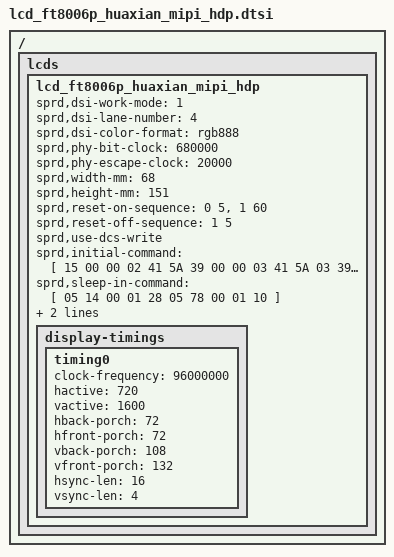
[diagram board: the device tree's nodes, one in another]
/ { lcds {
	lcd_ft8006p_huaxian_mipi_hdp: lcd_ft8006p_huaxian_mipi_hdp {

		sprd,dsi-work-mode = <1>; /* video burst mode*/
		sprd,dsi-lane-number = <4>;
		sprd,dsi-color-format = "rgb888";

		sprd,phy-bit-clock = <680000>;	/* kbps */
		sprd,phy-escape-clock = <20000>;/* kHz */

		sprd,width-mm = <68>;
		sprd,height-mm = <151>;

		sprd,reset-on-sequence = <0 5>, <1 60>;
		sprd,reset-off-sequence = <1 5>;

		sprd,use-dcs-write;

		sprd,initial-command = [
			/*-------------  Display Initial Code Setting  -------------------------*/
			/* Stop reload */
			15 00 00 02 41 5A

			/* VCOM */
			39 00 00 03 41 5A 03
			39 00 00 03 80 A9 00

			/*----------------------LCD initial code start----------------------*/
			/* Blank 9 */
			39 00 00 03 41 5A 09
			39 00 00 06 80 64 00 64 00 00
			/* Blank 10 */
			39 00 00 03 41 5A 0A
			39 00 00 11 80 A5 15 A5 AA A5 88 42 68 A6 03 07 01 5F 46 50 3C
			39 00 00 11 90 0C 0F 22 00 2A 18 64 00 88 03 00 EE EE 00 3F 2A
			39 00 00 11 A0 00 30 02 32 11 0D 60 01 FF FF 03 40 42 0F 94 11
			39 00 00 11 B0 E8 03 00 00 11 0D 60 00 FF FF 03 FF 34 0C 0F 0E
			39 00 00 0b C0 1F 03 00 08 20 34 00 00 00 00
			/* Blank 11 */
			39 00 00 03 41 5A 0B
			39 00 00 11 80 FF A0 A0 00 00 0A 1F 32 3C 47 58 65 66 73 74 87
			39 00 00 11 90 7D 6C 6E 63 5B 50 40 36 2C 1B 07 01 00 0A 1F 32
			39 00 00 11 A0 3C 47 58 65 66 73 74 87 7D 6C 6E 63 5B 50 40 36
			39 00 00 06 B0 2C 1B 07 01 00
			/* Blank 12 */
			39 00 00 03 41 5A 0C
			39 00 00 11 80 00 00 20 42 00 00 80 05 54 00 00 00 20 42 00 00
			39 00 00 03 90 80 05
			/* Blank 13 */
			39 00 00 03 41 5A 0D
			39 00 00 11 80 7A D0 02 40 06 D7 00 FA 00 0A 0A 0A 0A 00 01 03
			39 00 00 11 90 00 00 00 00 AC A2 2A 00 00 00 AC A2 2A 57 31 00
			39 00 00 11 A0 00 00 00 00 00 AC A2 2A AA C2 2A AC A2 2A AA C2
			39 00 00 07 B0 2A 00 00 00 AA 52
			/* Blank 14 */
			39 00 00 03 41 5A 0E
			39 00 00 0d 80 F0 B1 71 EF 4B 20 37 0F AA AA 00 00
			/* Blank 15 */
			39 00 00 03 41 5A 0F
			39 00 00 0c 80 FF 00 55 55 23 88 88 1C 00 5A 5A
			/* Blank 16 */
			39 00 00 03 41 5A 10
			39 00 00 11 80 B5 45 09 18 01 3C 94 32 10 C4 C4 04 00 60 C0 00
			39 00 00 11 90 04 00 00 86 10 31 98 34 34 34 26 26 3E 1A 62 20
			39 00 00 05 A0 0C 40 00 8A
			/* Blank 17 */
			39 00 00 03 41 5A 11
			39 00 00 11 80 00 00 03 E7 1F 17 10 48 80 AA 90 1A 30 88 41 8A
			39 00 00 10 90 39 28 A9 C5 9A 7B F0 07 7E E0 07 7E 20 10 00
			/* Blank 18 */
			39 00 00 03 41 5A 12
			39 00 00 11 80 00 00 00 00 00 00 00 00 00 00 00 00 00 00 41 37
			39 00 00 11 90 2D 23 19 0F 05 FB F1 E7 00 00 00 00 00 00 00 00
			39 00 00 11 A0 00 00 00 00 00 00 00 00 00 00 00 00 00 00 00 00
			39 00 00 11 B0 00 00 00 00 00 00 00 00 00 2D 23 05 FB 00 2D 23
			39 00 00 05 C0 05 FB 00 01
			/* Blank 19 */
			39 00 00 03 41 5A 13
			39 00 00 11 80 FD 0F 00 0C 00 80 80 82 00 07 22 06 E7 B9 86 1A
			39 00 00 11 90 32 00 A2 2D 65 00 00 00 00 D0 C9 B7 FE 26 6F 32
			39 00 00 04 A0 22 90 04
			/* Blank 20 */
			39 00 00 03 41 5A 14
			39 00 00 11 80 01 02 40 5E D1 DF EF F7 FB FD 02 00 00 20 8B 0D
			39 00 00 11 90 77 FA C0 16 78 24 04 36 C1 23 21 00 2B 23 F8 00
			39 00 00 11 A0 00 F8 FD 00 00 C0 EF 07 00 3F 06 6B C5 EF 8F 00
			39 00 00 11 B0 B0 13 BF 3F 02 00 00 00 00 88 64 48 56 00 80 42
			39 00 00 11 C0 A1 F0 06 DC 69 01 A3 00 5E 80 3B 2D 60 14 C0 2B
			39 00 00 11 D0 70 A7 05 8C 02 78 09 EE B4 80 51 00 AF C1 9D 16
			39 00 00 11 E0 30 06 E0 45 B8 D3 02 46 01 BC 0A 77 5A C0 28 80
			39 00 00 11 F0 97 E1 4E 0B 18 05 30 06 7E 3F 14 00 00 00 00 00
			/* Blank 21 */
			39 00 00 03 41 5A 15
			39 00 00 11 80 00 00 00 00 00 00 00 00 00 00 00 00 0C 80 FF EF
			39 00 00 11 90 27 03 43 C6 88 51 AB 0D A1 D5 3A 62 D4 6A 43 68
			39 00 00 11 A0 B5 00 00 00 00 00 00 00 00 00 00 00 00 00 00 00
			39 00 00 11 B0 00 00 00 00 00 00 00 00 26 00 E0 01 28 54 AB AE
			39 00 00 11 C0 66 DB B6 AD A3 B4 AD 21 44 6D DB B6 6D 0B B5 AB
			39 00 00 11 D0 6A B6 6D DB 02 44 DB 22 8C D4 B6 6D DB B6 52 AB
			39 00 00 11 E0 AE 66 DB B6 2D 83 B4 2D 01 40 6D DB B6 6D 1B B5
			39 00 00 11 F0 AB 6A B6 6D DB 0A 46 DB 2A 0E D5 B6 6D DB B6 00
			/* Blank 22 */
			39 00 00 03 41 5A 16
			39 00 00 11 80 00 00 00 00 00 00 00 00 00 00 00 00 00 00 00 00
			39 00 00 0b 90 00 00 00 00 A0 41 2A 01 00 00
			/* Blank 24 */
			39 00 00 03 41 5A 18
			39 00 00 11 80 EF BD F7 DE 7B EF BD 07 08 08 0A 0C 0C 0C 0C 0C
			39 00 00 11 90 0C 0C 0C 5C 09 A8 AA AA AA AA AA AA AA AA AA 5A
			39 00 00 11 A0 59 59 59 59 59 59 59 59 59 59 59 09 04 FF 00 80
			39 00 00 10 B0 80 00 04 20 00 01 08 40 00 02 10 80 00 04 00
			/* Blank 25 */
			39 00 00 03 41 5A 19
			39 00 00 11 80 C4 B5 A6 9B 93 8C 86 81 80 80 80 80 77 F7 FF FF
			39 00 00 11 90 FF 0F F0 BF 7F 4F 0F FF AF B5 71 0E 6C 4A 69 08
			39 00 00 05 A0 00 00 48 00
			/* Blank 26 */
			39 00 00 03 41 5A 1A
			39 00 00 11 80 FF 00 04 08 0C 00 10 14 18 1C 00 20 27 2F 37 FC
			39 00 00 11 90 3F 47 4F 57 AB 5F 67 6F 77 56 7F 87 8E 96 F0 9E
			39 00 00 11 A0 A6 AE B6 6B BE C6 CE D5 C1 DD E5 EC F4 56 F8 FA
			39 00 00 11 B0 FB 15 00 04 07 0B F0 0F 13 17 1B 6A 1F 27 2E 36
			39 00 00 11 C0 B1 3E 46 4E 55 C6 5D 65 6D 75 1B 7D 84 8C 94 AC
			39 00 00 11 D0 9C A4 AC B3 C1 BB C3 CB D3 16 DB E2 EA F2 BC F6
			39 00 00 11 E0 F8 F9 16 00 04 07 0B F0 0F 13 17 1B AF 1F 27 2F
			39 00 00 11 F0 37 FA 3F 47 4F 57 FF 5F 67 6F 77 AF 7F 87 8F 97
			/* Blank 27 */
			39 00 00 03 41 5A 1B
			39 00 00 11 80 05 9E A6 AE B6 6F BE C6 CE D6 01 DE E6 F0 F8 00
			39 00 00 06 90 FC FE FF 00 00
			/* Blank 28 */
			39 00 00 03 41 5A 1C
			39 00 00 11 80 33 22 00 03 5A 02 5A 54 E5 FF C7 20 18 28 18 08
			39 00 00 11 90 10 0C 07 09 06 06 0A 10 0C 09 0B 06 26 F2 78 40
			39 00 00 11 A0 20 08 08 06 13 C0 34 1E 0A 08 66 D1 A0 1C 20 20
			39 00 00 11 B0 18 04 20 00 C0 04 28 01 4C 00 23 18 10 0A 06 C9
			39 00 00 11 C0 04 70 41 58 54 B5 4A 55 15 00 78 F8 99 99 99 99
			39 00 00 11 D0 99 99 88 88 88 88 88 88 08 C4 E3 81 00 20 80 27
			39 00 00 11 E0 E2 89 00 00 00 00 40 00 80 30 04 41 06 00 00 00
			39 00 00 11 F0 00 92 24 49 92 04 00 00 00 00 92 04 00 C0 03 40
			/* Blank 29 */
			39 00 00 03 41 5A 1D
			39 00 00 11 80 00 01 54 0B 23 18 00 00 80 00 00 00 00 00 00 00
			/* Blank 34 */
			39 00 00 03 41 5A 22
			39 00 00 10 80 00 5E 00 00 00 00 00 00 5E 00 00 00 00 00 00
			/* Blank 36 */
			39 00 00 03 41 5A 24
			39 00 00 11 80 2D D3 00 55 55 55 55 55 55 55 55 1F 00 AA 3E 00
			39 00 00 05 90 00 00 00 00
			/* Blank 37 */
			39 00 00 03 41 5A 25
			39 00 00 11 80 01 05 00 05 00 00 00 00 00 00 00 00 00 00 00 FF
			39 00 00 0c 90 0F 00 00 24 00 00 00 00 FF 07 35
			/* Blank 38 */
			39 00 00 03 41 5A 26
			39 00 00 11 80 00 83 00 FB BF 60 00 01 00 00 00 00 00 00 6F 78
			39 00 00 04 90 5A A5 5A

			/*----------------------LCD initial code End----------------------*/

			/* SPI FINISH */
			15 00 00 02 90 A5
			/* Blank select 2F */
			39 00 00 03 41 00 2F

			/* INT CANCEL */
			15 00 00 02 4C 03

			05 78 00 01 29
			05 14 00 01 11
			/*-------------  Display Initial Setting end -------------------------*/
		];

		sprd,sleep-in-command = [
			05 14 00 01 28
			05 78 00 01 10
		];

		sprd,sleep-out-command = [
			05 78 00 01 11
			05 14 00 01 29
		];

		display-timings {
			timing0 {
				clock-frequency = <96000000>;
				hactive = <720>;
				vactive = <1600>;
				hback-porch = <72>;
				hfront-porch = <72>;
				vback-porch = <108>;
				vfront-porch = <132>;
				hsync-len = <16>;
				vsync-len = <4>;
			};
		};
	};
};};
